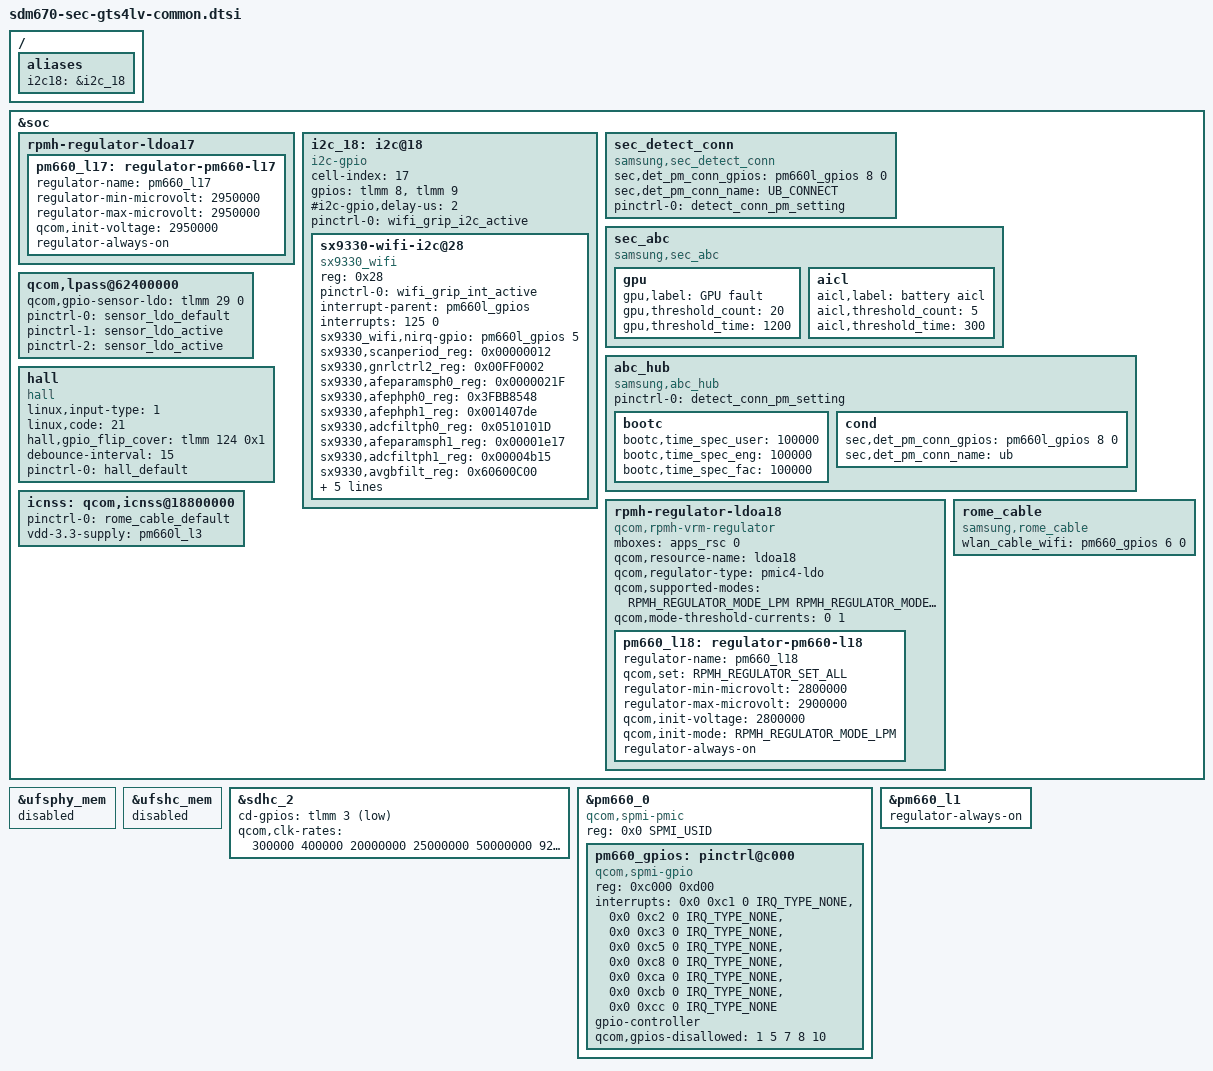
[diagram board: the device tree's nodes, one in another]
/* Copyright (c) 2016-2018, The Linux Foundation. All rights reserved.
 *
 * This program is free software; you can redistribute it and/or modify
 * it under the terms of the GNU General Public License version 2 and
 * only version 2 as published by the Free Software Foundation.
 *
 * This program is distributed in the hope that it will be useful,
 * but WITHOUT ANY WARRANTY; without even the implied warranty of
 * MERCHANTABILITY or FITNESS FOR A PARTICULAR PURPOSE.  See the
 * GNU General Public License for more details.
 */


#include "sdm670-sec-gts4lv-input-common.dtsi"
#include "sdm710-sec-gts4lv-audio.dtsi"
#include "sdm670-sec-gts4lv-fingerprint-sensor_00.dtsi"
#include <dt-bindings/spmi/spmi.h>
#include <dt-bindings/interrupt-controller/irq.h>
#include <dt-bindings/thermal/thermal.h>

#include <dt-bindings/regulator/qcom,rpmh-regulator.h>

/{
	aliases {
		i2c18 = &i2c_18;
	};
};

&soc {
	/* Grip Sensor */
	rpmh-regulator-ldoa17 {
		pm660_l17: regulator-pm660-l17 {
			regulator-name = "pm660_l17";
			regulator-min-microvolt = <2950000>;
			regulator-max-microvolt = <2950000>;
			qcom,init-voltage = <2950000>;
			regulator-always-on;
		};
	};

	/* Wifi Grip Sensor */
	i2c_18: i2c@18 { /* SW I2C */
		status = "ok";

		cell-index = <17>;
		compatible = "i2c-gpio";
		gpios = <&tlmm 8 0 /* sda */
			 &tlmm 9 0 /* scl */>;
		#i2c-gpio,delay-us = <2>;
		#address-cells = <1>;
		#size-cells = <0>;
		pinctrl-names = "default";
		pinctrl-0 = <&wifi_grip_i2c_active>;

		sx9330-wifi-i2c@28 {
			compatible = "sx9330_wifi";
			reg = <0x28>;
			pinctrl-names = "default";
			pinctrl-0 = <&wifi_grip_int_active>;

			interrupt-parent = <&pm660l_gpios>;
			interrupts = <125 0>;
			
			sx9330_wifi,nirq-gpio = <&pm660l_gpios 5 0>;
			
			sx9330,scanperiod_reg = <0x00000012>; /* scanperiod : 36ms */
			sx9330,gnrlctrl2_reg = <0x00FF0002>;
			sx9330,afeparamsph0_reg = <0x0000021F>;
			sx9330,afephph0_reg = <0x3FBB8548>;
			sx9330,afephph1_reg = <0x001407de>; /* compensation offset : 2014 */
			sx9330,adcfiltph0_reg = <0x0510101D>;
			sx9330,afeparamsph1_reg = <0x00001e17>; /* again : 5.5pF, sampling freq : 166.67 khz */
			sx9330,adcfiltph1_reg = <0x00004b15>;    /* threshold : 2812, strength of RAW filter : 0 */
			sx9330,avgbfilt_reg = <0x60600C00>;   /* AVGPOSFILT : 1/256, AVGNEGFILT : 1/2 */
			sx9330,avgafilt_reg = <0x00000000>;
			sx9330,advdig3_reg = <0x00000000>;
			sx9330,advdig4_reg = <0x00000000>;
			sx9330,refcorra_reg = <0x00000000>;
			sx9330,touchthd_ta_reg = <0x00008900>;  /* adcfiltph1 mask - threshold : 9947 */
		};
	};
	sec_detect_conn {
		compatible = "samsung,sec_detect_conn";
		/* sec,det_conn_gpios = <&tlmm ? 0>;  UB_CON_DETECT */					
		/* sec,det_conn_name = "UB_CONNECT";*/
		/* sec,det_conn_irq_type = <3>; UB_CON_DETECT FALLING, RIGING EDGE*/
		/* pinctrl-names = "det_ap_connect", "det_pm_connect"; */
		/* pinctrl-0 = <&detect_conn_setting>; */

		sec,det_pm_conn_gpios = <&pm660l_gpios 8 0>; /* UB_CONNECT */
		sec,det_pm_conn_name = "UB_CONNECT";

		pinctrl-names = "det_pm_connect";
		pinctrl-0 = <&detect_conn_pm_setting>;
	};

	sec_abc {
				compatible = "samsung,sec_abc";
				status = "okay";

				gpu {
					gpu,label="GPU fault";
					gpu,threshold_count=<20>;
					gpu,threshold_time=<1200>;
				};
				aicl {
					aicl,label="battery aicl";
					aicl,threshold_count=<5>;
					aicl,threshold_time=<300>;
				};
			};

	abc_hub {
		compatible = "samsung,abc_hub";
		status = "okay";

		pinctrl-names = "det_pm_connect";
		pinctrl-0 = <&detect_conn_pm_setting>;

		bootc {
			bootc,time_spec_user = <100000>; /* user binary user build */
			bootc,time_spec_eng = <100000>; /* user binary eng build */
			bootc,time_spec_fac = <100000>; /* factory binary */
		};

		cond {
			sec,det_pm_conn_gpios = <&pm660l_gpios 8 0>; /* UB_CONNECT */
			sec,det_pm_conn_name = "ub";
		};
	};
};

&ufsphy_mem{
	status = "disabled";
};

&ufshc_mem {
	status = "disabled";
};

&sdhc_2 {
	cd-gpios = <&tlmm 3 0x1>;
	qcom,clk-rates = <300000 400000 20000000 25000000
	   50000000 92300000 179100000>;
};

&soc {
	/* Sensor */
	qcom,lpass@62400000 {
		qcom,gpio-sensor-ldo = <&tlmm 29 0>;
		pinctrl-names = "default", "sleep", "idle";
		pinctrl-0 = <&sensor_ldo_default>;
		pinctrl-1 = <&sensor_ldo_active>;
		pinctrl-2 = <&sensor_ldo_active>;
	};

	hall {
                status = "okay";
                compatible = "hall";
                linux,input-type = <1>;
                linux,code = <21>;
                hall,gpio_flip_cover = <&tlmm 124 0x1>;
                debounce-interval = <15>;
		pinctrl-names = "default";
	        pinctrl-0 = <&hall_default>;
        };
	/*
        certify_hall {
		status = "okay";
                compatible = "certify_hall";
                linux,input-type = <1>;
                linux,code = <27>;
                certify_hall,gpio_certify_cover = <&tlmm 88 0x1>;
                debounce-interval = <15>;
		pinctrl-names = "default";
	        pinctrl-0 = <&certify_hall_default>;
        };
	*/
	/* RGB Sensor */
	rpmh-regulator-ldoa18 {
		compatible = "qcom,rpmh-vrm-regulator";
		mboxes = <&apps_rsc 0>;
		qcom,resource-name = "ldoa18";
		qcom,regulator-type = "pmic4-ldo";
		qcom,supported-modes =
			<RPMH_REGULATOR_MODE_LPM
			 RPMH_REGULATOR_MODE_HPM>;
		qcom,mode-threshold-currents = <0 1>;
		pm660_l18: regulator-pm660-l18 {
			regulator-name = "pm660_l18";
			qcom,set = <RPMH_REGULATOR_SET_ALL>;
			regulator-min-microvolt = <2800000>;
			regulator-max-microvolt = <2900000>;
			qcom,init-voltage = <2800000>;
			qcom,init-mode = <RPMH_REGULATOR_MODE_LPM>;
			regulator-always-on;
		};
	};
	icnss: qcom,icnss@18800000 {
		pinctrl-names = "default";
		pinctrl-0 = <&rome_cable_default>;
	};
	rome_cable {
		compatible = "samsung,rome_cable";
		wlan_cable_wifi = <&pm660_gpios 6 0>;
		status = "ok";
	};
};

&icnss {
	vdd-3.3-supply = <&pm660l_l3>;
};

&pm660_0 {
	compatible ="qcom,spmi-pmic";
	reg = <0x0 SPMI_USID>;
	#address-cells = <2>;
	#size-cells = <0>;

	pm660_gpios: pinctrl@c000 {
		compatible = "qcom,spmi-gpio";
		reg = <0xc000 0xd00>;
		interrupts = <0x0 0xc1 0 IRQ_TYPE_NONE>,
				<0x0 0xc2 0 IRQ_TYPE_NONE>,
				<0x0 0xc3 0 IRQ_TYPE_NONE>,
				<0x0 0xc5 0 IRQ_TYPE_NONE>,
				<0x0 0xc8 0 IRQ_TYPE_NONE>,
				<0x0 0xca 0 IRQ_TYPE_NONE>,
				<0x0 0xcb 0 IRQ_TYPE_NONE>,
				<0x0 0xcc 0 IRQ_TYPE_NONE>;
		interrupt-names = "pm660_gpio2", "pm660_gpio3",
				"pm660_gpio4", "pm660_gpio6",
				"pm660_gpio9", "pm660_gpio11",
				"pm660_gpio12", "pm660_gpio13";
		gpio-controller;
		#gpio-cells = <2>;
		qcom,gpios-disallowed = <1 5 7 8 10>;
	};
};

&pm660_l1 {
	regulator-always-on;
};
